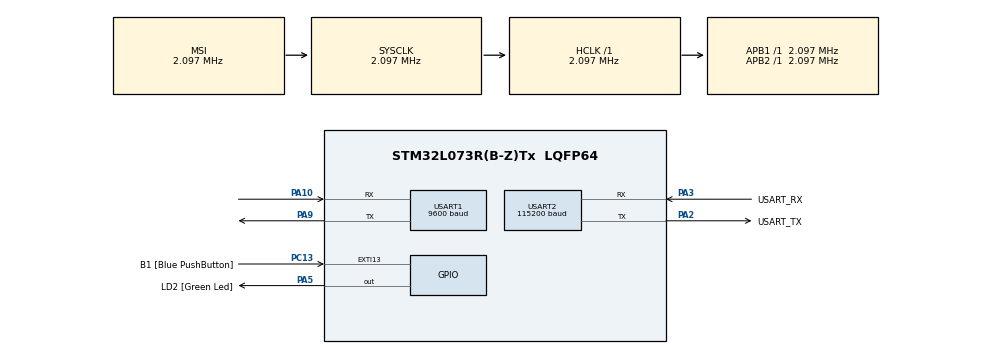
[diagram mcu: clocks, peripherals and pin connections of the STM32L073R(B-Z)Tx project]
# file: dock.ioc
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Mcu.Family=STM32L0
Mcu.Name=STM32L073R(B-Z)Tx
Mcu.Package=LQFP64
PA10.Mode=Asynchronous
PA10.Signal=USART1_RX
PA13.GPIO_Label=TMS
PA13.Mode=Serial_Wire
PA13.Signal=SYS_SWDIO
PA14.GPIO_Label=TCK
PA14.Mode=Serial_Wire
PA14.Signal=SYS_SWCLK
PA2.GPIO_Label=USART_TX
PA2.Mode=Asynchronous
PA2.Signal=USART2_TX
PA3.GPIO_Label=USART_RX
PA3.Mode=Asynchronous
PA3.Signal=USART2_RX
PA5.GPIO_Label=LD2 [Green Led]
PA5.Signal=GPIO_Output
PA9.Mode=Asynchronous
PA9.Signal=USART1_TX
PC13.GPIO_Label=B1 [Blue PushButton]
PC13.GPIO_ModeDefaultEXTI=GPIO_MODE_IT_FALLING
PC13.Signal=GPXTI13
PC14-OSC32_IN.Mode=LSE-External-Oscillator
PC14-OSC32_IN.Signal=RCC_OSC32_IN
PC15-OSC32_OUT.Mode=LSE-External-Oscillator
PC15-OSC32_OUT.Signal=RCC_OSC32_OUT
PH0-OSC_IN.GPIO_Label=MCO
PH0-OSC_IN.Mode=HSE-External-Clock-Source
PH0-OSC_IN.Signal=RCC_OSC_IN
ProjectManager.HeapSize=0x200
ProjectManager.StackSize=0x400
ProjectManager.TargetToolchain=STM32CubeIDE
RCC.AHBFreq_Value=2097000
RCC.APB1Freq_Value=2097000
RCC.APB1TimFreq_Value=2097000
RCC.APB2Freq_Value=2097000
RCC.APB2TimFreq_Value=2097000
RCC.HSE_VALUE=8000000
RCC.HSI16_VALUE=16000000
RCC.HSI48_VALUE=48000000
RCC.HSI_VALUE=16000000
RCC.MSI_VALUE=2097000
RCC.SYSCLKFreq_VALUE=2097000
RCC.VCOOutputFreq_Value=48000000
USART1.BaudRate=9600
USART1.VirtualMode-Asynchronous=VM_ASYNC
USART2.BaudRate=115200
USART2.VirtualMode-Asynchronous=VM_ASYNC
board=NUCLEO-L073RZ

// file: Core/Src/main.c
/* USER CODE BEGIN Header */
/**
  ******************************************************************************
  * @file           : main.c
  * @brief          : Main program body
  ******************************************************************************
  * @attention
  *
  * Copyright (c) 2024 STMicroelectronics.
  * All rights reserved.
  *
  * This software is licensed under terms that can be found in the LICENSE file
  * in the root directory of this software component.
  * If no LICENSE file comes with this software, it is provided AS-IS.
  *
  ******************************************************************************
  */
/* USER CODE END Header */
#include "main.h"

/* USER CODE BEGIN Includes */
#include "stdbool.h"
#include "string.h"
/* USER CODE END Includes */

UART_HandleTypeDef huart1;
UART_HandleTypeDef huart2;

/* USER CODE BEGIN PV */
char receive1[500];
char *RecBuff1   = receive1;

char receive2[1000];
char *RecBuff2  = receive2;

char newline[] = "\n";
/* USER CODE END PV */

void SystemClock_Config(void);
static void MX_GPIO_Init(void);
static void MX_USART2_UART_Init(void);
static void MX_USART1_UART_Init(void);
/* USER CODE BEGIN PFP */
void at_command(char *command);

/* USER CODE END PFP */

int main(void)
{

  /* MCU Configuration--------------------------------------------------------*/

  /* Reset of all peripherals, Initializes the Flash interface and the Systick. */
  HAL_Init();

  /* Configure the system clock */
  SystemClock_Config();

  /* Initialize all configured peripherals */
  MX_GPIO_Init();
  MX_USART2_UART_Init();
  MX_USART1_UART_Init();

  /* Infinite loop */
  /* USER CODE BEGIN WHILE */
//  while (1)
//  {
//	  if(HAL_GPIO_ReadPin(GPIOC, GPIO_PIN_13)== 0)
//	  {
    /* USER CODE END WHILE */
//	  at_command("AT\r\n");
//	  HAL_Delay(1000);
//	  at_command("AT\r\n");
//	  at_command("AT+RTC\r\n");
//	  at_command("AT+COMMAND=?");
//	  at_command("AT+TEST=?");
//	  at_command("AT+RTC=\"2024-06-05 17:01:00\"\r\n");
//	  at_command("AT+DR=SCHEME\r\n");
//	  at_command("AT+DR=band\r\n");
//	  HAL_Delay(1000);
//	  at_command("AT+TEMP\r\n");
//	  HAL_Delay(1000);
//  	  at_command("AT+MODE=TEST\r\n");
//  	  at_command("AT+TEST=?\r\n");
//  	  at_command("AT+TEST=RFCFG,433,SF12,125,12,15,14,ON,OFF,OFF\r\n");
//  	  AT+TEST=RFCFG,868000000,7,125,8,8,14,1,0,0\r\n
//  	  at_command("AT+TEST=TXLRSTR, \"TEST\"\r\n");
//  	AT+TEST=RFCFG,868000000,7,125,8,8,14,1,0,0\r\n
//  at_command("AT+PMSG=\"Data to send\"\r\n");
//  at_command("AT+REG\r\n");

//  at_command("AT+TEST=TXCW\r\n");
//  at_command("AT+TEST=TXCLORA\r\n");
//	  at_command("AT+DR\r\n");
//	  at_command("AT+DR=EU433\r\n");
  	  at_command("AT+CH\r\n");
//	  at_command("AT+CH=0, 433.3, DR7\r\n");
//	  at_command("AT+CH=0\r\n");
//	  at_command("AT+CH=1\r\n");
//	  at_command("AT+CH=2\r\n");
//	  at_command("AT+CH=3\r\n");
//	  at_command("AT+CH=3,433.3, DR7\r\n");
  	  at_command("AT+HELP\r\n");
//    at_command("AT+LW=CT, ON\r\n");
  	  at_command("AT+MODE=TEST\r\n");
  	  at_command("AT+TEST=?\r\n");
//  	  at_command("AT+PMSG=\"This is a string\"\r\n");
//    at_command("AT+TEST=RFCFG,433,SF12,125,12,15,14,ON,OFF,OFF\r\n");
//    at_command("AT+TEST=TXLRSTR, \"TEST\"\r\n");

    /* USER CODE BEGIN 3 */
//	  }
//  }
  /* USER CODE END 3 */
}

void at_command(char *command)
{
	int i;
	uint8_t j=0;

	for (i=0; i< strlen(command); i++)
	{
		HAL_UART_Transmit(&huart1, (uint8_t *)&command[i], 1, 100);
	}

	 while (j < 1)
	  {
	    for (i = 0;; i++)
	    {
	      HAL_UART_Receive(&huart1, (uint8_t *)&receive1[i], 1, 100);
	      RecBuff1++;

	      if (receive1[i] == '\0')
	      {
	        j++;
	        HAL_UART_Transmit(&huart2, (uint8_t *)receive1, i, 100);
	        HAL_UART_Transmit(&huart2, (uint8_t *)newline, 1, 100);

	        memset(receive1, 0x00, sizeof(receive1));
	        break;
	      }
	    }
	  }

	  j = 0;

}
void SystemClock_Config(void)
{
  RCC_OscInitTypeDef RCC_OscInitStruct = {0};
  RCC_ClkInitTypeDef RCC_ClkInitStruct = {0};
  RCC_PeriphCLKInitTypeDef PeriphClkInit = {0};

  /** Configure the main internal regulator output voltage
  */
  __HAL_PWR_VOLTAGESCALING_CONFIG(PWR_REGULATOR_VOLTAGE_SCALE1);

  /** Initializes the RCC Oscillators according to the specified parameters
  * in the RCC_OscInitTypeDef structure.
  */
  RCC_OscInitStruct.OscillatorType = RCC_OSCILLATORTYPE_MSI;
  RCC_OscInitStruct.MSIState = RCC_MSI_ON;
  RCC_OscInitStruct.MSICalibrationValue = 0;
  RCC_OscInitStruct.MSIClockRange = RCC_MSIRANGE_5;
  RCC_OscInitStruct.PLL.PLLState = RCC_PLL_NONE;
  if (HAL_RCC_OscConfig(&RCC_OscInitStruct) != HAL_OK)
  {
    Error_Handler();
  }

  /** Initializes the CPU, AHB and APB buses clocks
  */
  RCC_ClkInitStruct.ClockType = RCC_CLOCKTYPE_HCLK|RCC_CLOCKTYPE_SYSCLK
                              |RCC_CLOCKTYPE_PCLK1|RCC_CLOCKTYPE_PCLK2;
  RCC_ClkInitStruct.SYSCLKSource = RCC_SYSCLKSOURCE_MSI;
  RCC_ClkInitStruct.AHBCLKDivider = RCC_SYSCLK_DIV1;
  RCC_ClkInitStruct.APB1CLKDivider = RCC_HCLK_DIV1;
  RCC_ClkInitStruct.APB2CLKDivider = RCC_HCLK_DIV1;

  if (HAL_RCC_ClockConfig(&RCC_ClkInitStruct, FLASH_LATENCY_0) != HAL_OK)
  {
    Error_Handler();
  }
  PeriphClkInit.PeriphClockSelection = RCC_PERIPHCLK_USART1|RCC_PERIPHCLK_USART2;
  PeriphClkInit.Usart1ClockSelection = RCC_USART1CLKSOURCE_PCLK2;
  PeriphClkInit.Usart2ClockSelection = RCC_USART2CLKSOURCE_PCLK1;
  if (HAL_RCCEx_PeriphCLKConfig(&PeriphClkInit) != HAL_OK)
  {
    Error_Handler();
  }
}

static void MX_USART1_UART_Init(void)
{

  huart1.Instance = USART1;
  huart1.Init.BaudRate = 9600;
  huart1.Init.WordLength = UART_WORDLENGTH_8B;
  huart1.Init.StopBits = UART_STOPBITS_1;
  huart1.Init.Parity = UART_PARITY_NONE;
  huart1.Init.Mode = UART_MODE_TX_RX;
  huart1.Init.HwFlowCtl = UART_HWCONTROL_NONE;
  huart1.Init.OverSampling = UART_OVERSAMPLING_16;
  huart1.Init.OneBitSampling = UART_ONE_BIT_SAMPLE_DISABLE;
  huart1.AdvancedInit.AdvFeatureInit = UART_ADVFEATURE_NO_INIT;
  if (HAL_UART_Init(&huart1) != HAL_OK)
  {
    Error_Handler();
  }

}

static void MX_USART2_UART_Init(void)
{

  huart2.Instance = USART2;
  huart2.Init.BaudRate = 115200;
  huart2.Init.WordLength = UART_WORDLENGTH_8B;
  huart2.Init.StopBits = UART_STOPBITS_1;
  huart2.Init.Parity = UART_PARITY_NONE;
  huart2.Init.Mode = UART_MODE_TX_RX;
  huart2.Init.HwFlowCtl = UART_HWCONTROL_NONE;
  huart2.Init.OverSampling = UART_OVERSAMPLING_16;
  huart2.Init.OneBitSampling = UART_ONE_BIT_SAMPLE_DISABLE;
  huart2.AdvancedInit.AdvFeatureInit = UART_ADVFEATURE_NO_INIT;
  if (HAL_UART_Init(&huart2) != HAL_OK)
  {
    Error_Handler();
  }

}

static void MX_GPIO_Init(void)
{
  GPIO_InitTypeDef GPIO_InitStruct = {0};

  /* GPIO Ports Clock Enable */
  __HAL_RCC_GPIOC_CLK_ENABLE();
  __HAL_RCC_GPIOH_CLK_ENABLE();
  __HAL_RCC_GPIOA_CLK_ENABLE();

  /*Configure GPIO pin Output Level */
  HAL_GPIO_WritePin(LD2_GPIO_Port, LD2_Pin, GPIO_PIN_RESET);

  /*Configure GPIO pin : B1_Pin */
  GPIO_InitStruct.Pin = B1_Pin;
  GPIO_InitStruct.Mode = GPIO_MODE_IT_FALLING;
  GPIO_InitStruct.Pull = GPIO_NOPULL;
  HAL_GPIO_Init(B1_GPIO_Port, &GPIO_InitStruct);

  /*Configure GPIO pin : LD2_Pin */
  GPIO_InitStruct.Pin = LD2_Pin;
  GPIO_InitStruct.Mode = GPIO_MODE_OUTPUT_PP;
  GPIO_InitStruct.Pull = GPIO_NOPULL;
  GPIO_InitStruct.Speed = GPIO_SPEED_FREQ_LOW;
  HAL_GPIO_Init(LD2_GPIO_Port, &GPIO_InitStruct);

}

void Error_Handler(void)
{
  __disable_irq();
  while (1)
  {
  }
}
